# ESP32-S3 register map
Vendor: ESPRESSIF SYSTEMS (SHANGHAI) CO., LTD.; Series: ESP32-S3; File version: 7
CPU: Xtensa LX7 r0p0, little endian, no MPU, FPU, 3 interrupt priority bits
Address unit: 32 bits
Registers are 32-bit, read-write, reset 0x0 unless marked. A register's access mark holds for its fields unless they carry their own. Offsets are from the block's base; [hi:lo] are bit positions; {n}, {i} and the like mark numbered series.

## LEDC — LED PWM (Pulse Width Modulation) Controller
Base 0x60019000
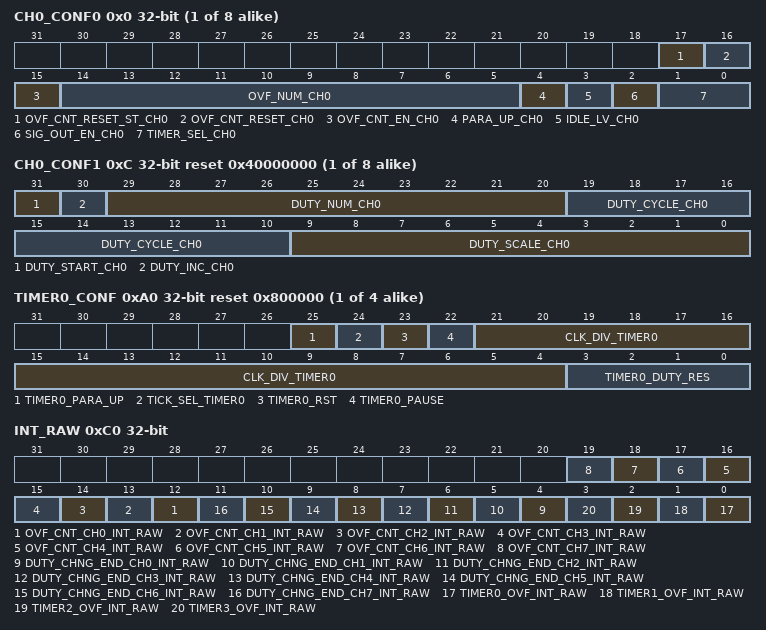
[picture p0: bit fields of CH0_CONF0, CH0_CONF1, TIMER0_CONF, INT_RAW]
{0x0+0x14*i} CH{i}_CONF0 (i=0..7) access per field — Configuration register 0 for channel {i}
  [17] OVF_CNT_RESET_ST_CH0 ro — This is the status bit of LEDC_OVF_CNT_RESET_CH%s.
  [16] OVF_CNT_RESET_CH0 wo — Set this bit to reset the ovf_cnt of channel %s.
  [15] OVF_CNT_EN_CH0 rw — This bit is used to enable the ovf_cnt of channel %s.
  [14:5] OVF_NUM_CH0 rw — This register is used to configure the maximum times of overflow minus 1. The LEDC_OVF_CNT_CH%s_INT interrupt will be triggered when channel %s overflows for (LEDC_OVF_NUM_CH%s + 1) times.
  [4] PARA_UP_CH0 wo — This bit is used to update LEDC_HPOINT_CH%s, LEDC_DUTY_START_CH%s, LEDC_SIG_OUT_EN_CH%s, LEDC_TIMER_SEL_CH%s, LEDC_DUTY_NUM_CH%s, LEDC_DUTY_CYCLE_CH%s, LEDC_DUTY_SCALE_CH%s, LEDC_DUTY_INC_CH%s, and LEDC_OVF_CNT_EN_CH%s fields for channel %s, and will be automatically cleared by hardware.
  [3] IDLE_LV_CH0 rw — This bit is used to control the output value when channel %s is inactive (when LEDC_SIG_OUT_EN_CH%s is 0).
  [2] SIG_OUT_EN_CH0 rw — Set this bit to enable signal output on channel %s.
  [1:0] TIMER_SEL_CH0 rw — This field is used to select one of timers for channel %s. 0: select timer0 1: select timer1 2: select timer2 3: select timer3
{0x4+0x14*i} CH{i}_HPOINT (i=0..7) — High point register for channel {i}
  [13:0] HPOINT_CH0 — The output value changes to high when the selected timers has reached the value specified by this register.
{0x8+0x14*i} CH{i}_DUTY (i=0..7) — Initial duty cycle for channel {i}
  [18:0] DUTY_CH0 — This register is used to change the output duty by controlling the Lpoint. The output value turns to low when the selected timers has reached the Lpoint.
{0xC+0x14*i} CH{i}_CONF1 (i=0..7) reset 0x40000000 — Configuration register 1 for channel {i}
  [31] DUTY_START_CH0 — Other configured fields in LEDC_CH%s_CONF1_REG will start to take effect when this bit is set to 1.
  [30] DUTY_INC_CH0 — This register is used to increase or decrease the duty of output signal on channel %s. 1: Increase; 0: Decrease.
  [29:20] DUTY_NUM_CH0 — This register is used to control the number of times the duty cycle will be changed.
  [19:10] DUTY_CYCLE_CH0 — The duty will change every LEDC_DUTY_CYCLE_CH%s on channel %s.
  [9:0] DUTY_SCALE_CH0 — This register is used to configure the changing step scale of duty on channel %s.
{0x10+0x14*i} CH{i}_DUTY_R (i=0..7) ro — Current duty cycle for channel {i}
  [18:0] DUTY_R_CH0 — This register stores the current duty of output signal on channel %s.
{0xA0+8i} TIMER{i}_CONF (i=0..3) access per field reset 0x800000 — Timer {i} configuration
  [25] TIMER0_PARA_UP wo — Set this bit to update LEDC_CLK_DIV_TIMER%s and LEDC_TIMER%s_DUTY_RES.
  [24] TICK_SEL_TIMER0 rw — This bit is used to select clock for timer %s. When this bit is set to 1 LEDC_APB_CLK_SEL[1:0] should be 1, otherwise the timer clock may be not accurate. 1'h0: SLOW_CLK 1'h1: REF_TICK
  [23] TIMER0_RST rw — This bit is used to reset timer %s. The counter will show 0 after reset.
  [22] TIMER0_PAUSE rw — This bit is used to suspend the counter in timer %s.
  [21:4] CLK_DIV_TIMER0 rw — This register is used to configure the divisor for the divider in timer %s. The least significant eight bits represent the fractional part.
  [3:0] TIMER0_DUTY_RES rw — This register is used to control the range of the counter in timer %s.
{0xA4+8i} TIMER{i}_VALUE (i=0..3) ro — Timer {i} current counter value
  [13:0] TIMER0_CNT — This register stores the current counter value of timer %s.
0xC0 INT_RAW ro — Raw interrupt status
  [n+12] OVF_CNT_CH{n}_INT_RAW (n=0..7) — Interrupt raw bit for channel {n}. Triggered when the ovf_cnt has reached the value specified by LEDC_OVF_NUM_CH{n}.
  [n+4] DUTY_CHNG_END_CH{n}_INT_RAW (n=0..7) — Interrupt raw bit for channel {n}. Triggered when the gradual change of duty has finished.
  [n] TIMER{n}_OVF_INT_RAW (n=0..3) — Triggered when the timer{n} has reached its maximum counter value.
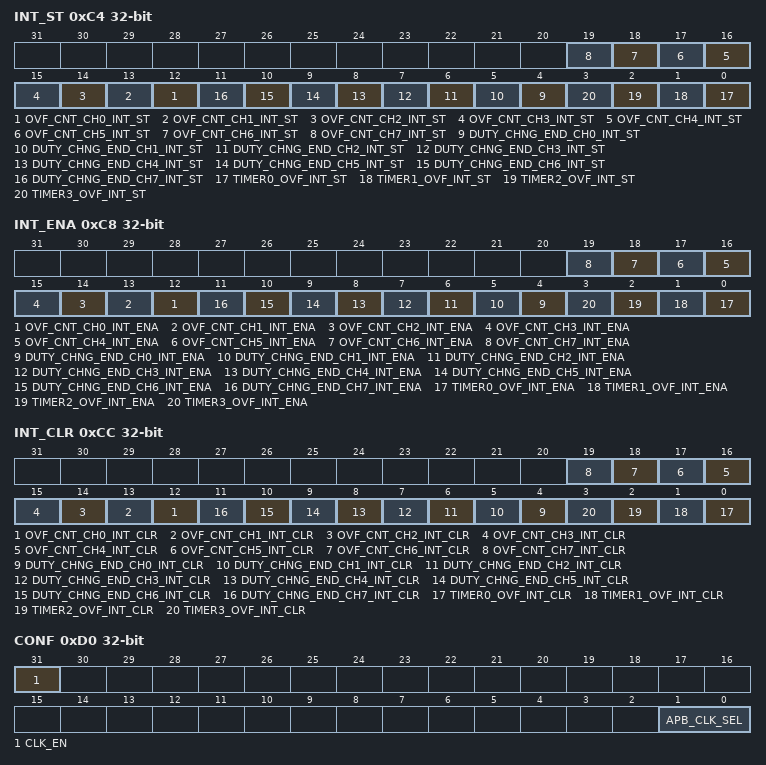
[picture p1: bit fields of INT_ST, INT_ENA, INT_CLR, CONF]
0xC4 INT_ST ro — Masked interrupt status
  [n+12] OVF_CNT_CH{n}_INT_ST (n=0..7) — This is the masked interrupt status bit for the LEDC_OVF_CNT_CH{n}_INT interrupt when LEDC_OVF_CNT_CH{n}_INT_ENA is set to 1.
  [n+4] DUTY_CHNG_END_CH{n}_INT_ST (n=0..7) — This is the masked interrupt status bit for the LEDC_DUTY_CHNG_END_CH{n}_INT interrupt when LEDC_DUTY_CHNG_END_CH{n}_INT_ENAIS set to 1.
  [n] TIMER{n}_OVF_INT_ST (n=0..3) — This is the masked interrupt status bit for the LEDC_TIMER{n}_OVF_INT interrupt when LEDC_TIMER{n}_OVF_INT_ENA is set to 1.
0xC8 INT_ENA — Interrupt enable bits
  [n+12] OVF_CNT_CH{n}_INT_ENA (n=0..7) — The interrupt enable bit for the LEDC_OVF_CNT_CH{n}_INT interrupt.
  [n+4] DUTY_CHNG_END_CH{n}_INT_ENA (n=0..7) — The interrupt enable bit for the LEDC_DUTY_CHNG_END_CH{n}_INT interrupt.
  [n] TIMER{n}_OVF_INT_ENA (n=0..3) — The interrupt enable bit for the LEDC_TIMER{n}_OVF_INT interrupt.
0xCC INT_CLR wo — Interrupt clear bits
  [n+12] OVF_CNT_CH{n}_INT_CLR (n=0..7) — Set this bit to clear the LEDC_OVF_CNT_CH{n}_INT interrupt.
  [n+4] DUTY_CHNG_END_CH{n}_INT_CLR (n=0..7) — Set this bit to clear the LEDC_DUTY_CHNG_END_CH{n}_INT interrupt.
  [n] TIMER{n}_OVF_INT_CLR (n=0..3) — Set this bit to clear the LEDC_TIMER{n}_OVF_INT interrupt.
0xD0 CONF — Global ledc configuration register
  [31] CLK_EN — This bit is used to control clock. 1'b1: Force clock on for register. 1'h0: Support clock only when application writes registers.
  [1:0] APB_CLK_SEL — This bit is used to select clock source for the 4 timers . 2'd1: APB_CLK 2'd2: RTC8M_CLK 2'd3: XTAL_CLK
0xFC DATE reset 0x19040200 — Version control register
  [31:0] DATE — This is the version control register.
